# apollo510 register map
Vendor: Ambiq Micro; Series: Apollo; File version: 1.0
CPU: CM55 r1p1, little endian, MPU, FPU, double-precision FPU, DSP, I-cache, D-cache, VTOR, ITCM, DTCM, 4 interrupt priority bits, 0 interrupts, 8 SAU regions
Registers are 32-bit, read-write, reset 0x0 unless marked. A register's access mark holds for its fields unless they carry their own. Offsets are from the block's base; [hi:lo] are bit positions; {n}, {i} and the like mark numbered series; 'fields as' and 'values as' point back to an identical list.

## TIMER — Counter/Timer
Base 0x40008000
0x00 CTRL — General Timer Controls
  [31] RESET — Write to 1 to reset all timers (self-clearing)
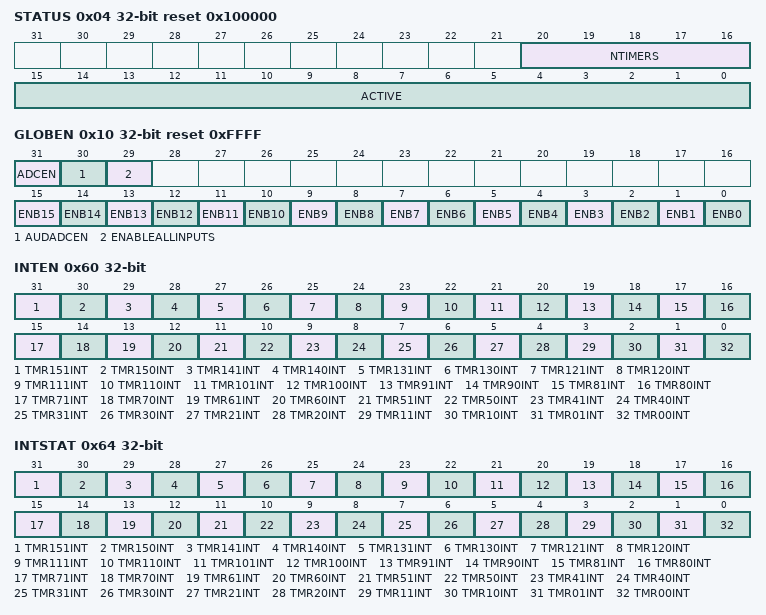
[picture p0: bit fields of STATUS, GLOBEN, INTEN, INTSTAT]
0x04 STATUS reset 0x100000 — General Timer status
  [20:16] NTIMERS — Indicates the number of timer blocks present in the design
  [15:0] ACTIVE — Indicates which timers are currnetly active (enabled)
0x10 GLOBEN reset 0xFFFF — Alternate enables for all TIMERs.
  [31] ADCEN — ADC controls enable for timer 7
    1=EN (Timer Enabled. TMREN enable is used.); 0=DIS (Disable TIMER .)
  [30] AUDADCEN — Audio ADC controls enable for timer 6
    values as ADCEN
  [29] ENABLEALLINPUTS — Override to enable all GPIO inputs
    1=EN (Override to enable all inputs from GPIO); 0=DIS (Normal mode where inputs from GPIO are enabled based on enabled clock and triggers.)
  [n] ENB{n} (n=0..15) — Alternate enable for timer {n}
    1=EN (Timer Enabled. TMR{n}EN enable is used.); 0=DIS (Disable TIMER {n}.)
0x60 INTEN — Set bits in this register to allow this module to generate the corresponding interrupt.
  [31] TMR151INT — Counter/Timer 15 interrupt based on CMP1.
  [30] TMR150INT — Counter/Timer 15 interrupt based on CMP0.
  [29] TMR141INT — Counter/Timer 14 interrupt based on CMP1.
  [28] TMR140INT — Counter/Timer 14 interrupt based on CMP0.
  [27] TMR131INT — Counter/Timer 13 interrupt based on CMP1.
  [26] TMR130INT — Counter/Timer 13 interrupt based on CMP0.
  [25] TMR121INT — Counter/Timer 12 interrupt based on CMP1.
  [24] TMR120INT — Counter/Timer 12 interrupt based on CMP0.
  [23] TMR111INT — Counter/Timer 11 interrupt based on CMP1.
  [22] TMR110INT — Counter/Timer 11 interrupt based on CMP0.
  [21] TMR101INT — Counter/Timer 10 interrupt based on CMP1.
  [20] TMR100INT — Counter/Timer 10 interrupt based on CMP0.
  [19] TMR91INT — Counter/Timer 9 interrupt based on CMP1.
  [18] TMR90INT — Counter/Timer 9 interrupt based on CMP0.
  [17] TMR81INT — Counter/Timer 8 interrupt based on CMP1.
  [16] TMR80INT — Counter/Timer 8 interrupt based on CMP0.
  [15] TMR71INT — Counter/Timer 7 interrupt based on CMP1.
  [14] TMR70INT — Counter/Timer 7 interrupt based on CMP0.
  [13] TMR61INT — Counter/Timer 6 interrupt based on CMP1.
  [12] TMR60INT — Counter/Timer 6 interrupt based on CMP0.
  [11] TMR51INT — Counter/Timer 5 interrupt based on CMP1.
  [10] TMR50INT — Counter/Timer 5 interrupt based on CMP0.
  [9] TMR41INT — Counter/Timer 4 interrupt based on CMP1.
  [8] TMR40INT — Counter/Timer 4 interrupt based on CMP0.
  [7] TMR31INT — Counter/Timer 3 interrupt based on CMP1.
  [6] TMR30INT — Counter/Timer 3 interrupt based on CMP0.
  [5] TMR21INT — Counter/Timer 2 interrupt based on CMP1.
  [4] TMR20INT — Counter/Timer 2 interrupt based on CMP0.
  [3] TMR11INT — Counter/Timer 1 interrupt based on CMP1.
  [2] TMR10INT — Counter/Timer 1 interrupt based on CMP0.
  [1] TMR01INT — Counter/Timer 0 interrupt based on CMP1.
  [0] TMR00INT — Counter/Timer 0 interrupt based on CMP0.
0x64 INTSTAT — Read bits from this register to discover the cause of a recent interrupt.
  fields as INTEN
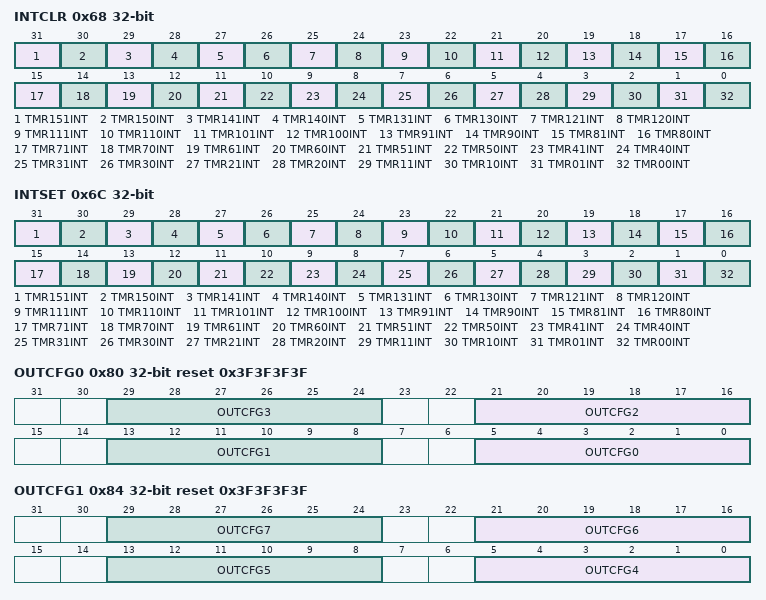
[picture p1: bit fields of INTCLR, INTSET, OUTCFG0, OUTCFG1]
0x68 INTCLR — Write a 1 to a bit in this register to clear the interrupt status associated with that bit.
  fields as INTEN
0x6C INTSET — Write a 1 to a bit in this register to instantly generate an interrupt from this module. (Generally used for testing purposes).
  fields as INTEN
0x80 OUTCFG0 reset 0x3F3F3F3F — Counter/Timer or System Timer output selections for GPIO pads.
  [all] fields
    0=TIMER00 (Output is Timer 0, output 0); 1=TIMER01 (Output is Timer 0, output 1); 2=TIMER10 (Output is Timer 1, output 0); 3=TIMER11 (Output is Timer 1, output 1); 4=TIMER20 (Output is Timer 2, output 0); 5=TIMER21 (Output is Timer 2, output 1); 6=TIMER30 (Output is Timer 3, output 0); 7=TIMER31 (Output is Timer 3, output 1); 8=TIMER40 (Output is Timer 4, output 0); 9=TIMER41 (Output is Timer 4, output 1); 10=TIMER50 (Output is Timer 5, output 0); 11=TIMER51 (Output is Timer 5, output 1); 12=TIMER60 (Output is Timer 6, output 0); 13=TIMER61 (Output is Timer 6, output 1); 14=TIMER70 (Output is Timer 7, output 0); 15=TIMER71 (Output is Timer 7, output 1); 16=TIMER80 (Output is Timer 8, output 0); 17=TIMER81 (Output is Timer 8, output 1); 18=TIMER90 (Output is Timer 9, output 0); 19=TIMER91 (Output is Timer 9, output 1); 20=TIMER100 (Output is Timer 10, output 0); 21=TIMER101 (Output is Timer 10, output 1); 22=TIMER110 (Output is Timer 11, output 0); 23=TIMER111 (Output is Timer 11, output 1); 24=TIMER120 (Output is Timer 12, output 0); 25=TIMER121 (Output is Timer 12, output 1); 26=TIMER130 (Output is Timer 13, output 0); 27=TIMER131 (Output is Timer 13, output 1); 28=TIMER140 (Output is Timer 14, output 0); 29=TIMER141 (Output is Timer 14, output 1); 30=TIMER150 (Output is Timer 15, output 0); 31=TIMER151 (Output is Timer 15, output 1); {v}=STIMER{v-32} (Output is STimer {v-32}) (v=32..39); 63=DISABLED (Output is disabled)
  [8n+5:8n] OUTCFG{n} (n=0..3) — Counter/Timer or System Timer output selection for GPIO{n}. Select an output of any timer to be output on this GPIO.
0x84 OUTCFG1 reset 0x3F3F3F3F — Counter/Timer or System Timer output selections for GPIO pads.
  [all] fields
    values as the fields of OUTCFG0
  [8n-27:8n-32] OUTCFG{n} (n=4..7) — Counter/Timer or System Timer output selection for GPIO{n}. Select an output of any timer to be output on this GPIO.
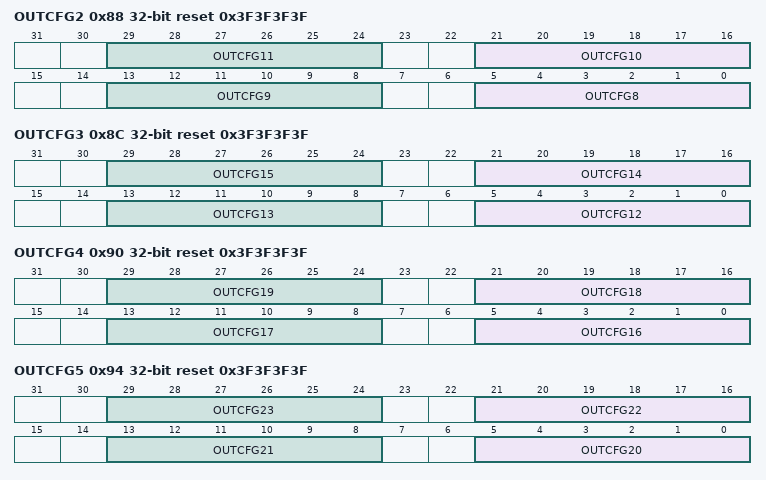
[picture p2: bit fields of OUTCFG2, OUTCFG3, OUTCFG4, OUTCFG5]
0x88 OUTCFG2 reset 0x3F3F3F3F — Counter/Timer or System Timer output selections for GPIO pads.
  [all] fields
    values as the fields of OUTCFG0
  [8n-59:8n-64] OUTCFG{n} (n=8..11) — Counter/Timer or System Timer output selection for GPIO{n}. Select an output of any timer to be output on this GPIO.
0x8C OUTCFG3 reset 0x3F3F3F3F — Counter/Timer or System Timer output selections for GPIO pads.
  [all] fields
    values as the fields of OUTCFG0
  [8n-91:8n-96] OUTCFG{n} (n=12..15) — Counter/Timer or System Timer output selection for GPIO{n}. Select an output of any timer to be output on this GPIO.
0x90 OUTCFG4 reset 0x3F3F3F3F — Counter/Timer or System Timer output selections for GPIO pads.
  [all] fields
    values as the fields of OUTCFG0
  [8n-123:8n-128] OUTCFG{n} (n=16..19) — Counter/Timer or System Timer output selection for GPIO{n}. Select an output of any timer to be output on this GPIO.
0x94 OUTCFG5 reset 0x3F3F3F3F — Counter/Timer or System Timer output selections for GPIO pads.
  [all] fields
    values as the fields of OUTCFG0
  [8n-155:8n-160] OUTCFG{n} (n=20..23) — Counter/Timer or System Timer output selection for GPIO{n}. Select an output of any timer to be output on this GPIO.
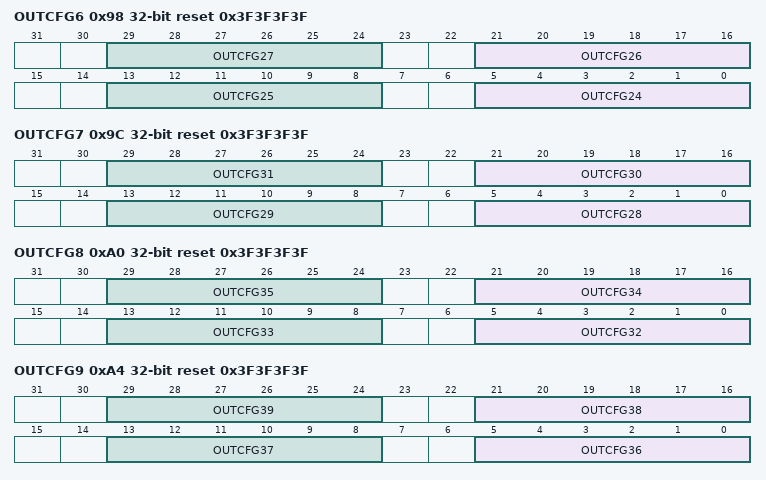
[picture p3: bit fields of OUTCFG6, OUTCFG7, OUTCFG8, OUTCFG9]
0x98 OUTCFG6 reset 0x3F3F3F3F — Counter/Timer or System Timer output selections for GPIO pads.
  [all] fields
    values as the fields of OUTCFG0
  [8n-187:8n-192] OUTCFG{n} (n=24..27) — Counter/Timer or System Timer output selection for GPIO{n}. Select an output of any timer to be output on this GPIO.
0x9C OUTCFG7 reset 0x3F3F3F3F — Counter/Timer or System Timer output selections for GPIO pads.
  [all] fields
    values as the fields of OUTCFG0
  [8n-219:8n-224] OUTCFG{n} (n=28..31) — Counter/Timer or System Timer output selection for GPIO{n}. Select an output of any timer to be output on this GPIO.
0xA0 OUTCFG8 reset 0x3F3F3F3F — Counter/Timer or System Timer output selections for GPIO pads.
  [all] fields
    values as the fields of OUTCFG0
  [8n-251:8n-256] OUTCFG{n} (n=32..35) — Counter/Timer or System Timer output selection for GPIO{n}. Select an output of any timer to be output on this GPIO.
0xA4 OUTCFG9 reset 0x3F3F3F3F — Counter/Timer or System Timer output selections for GPIO pads.
  [all] fields
    values as the fields of OUTCFG0
  [8n-283:8n-288] OUTCFG{n} (n=36..39) — Counter/Timer or System Timer output selection for GPIO{n}. Select an output of any timer to be output on this GPIO.
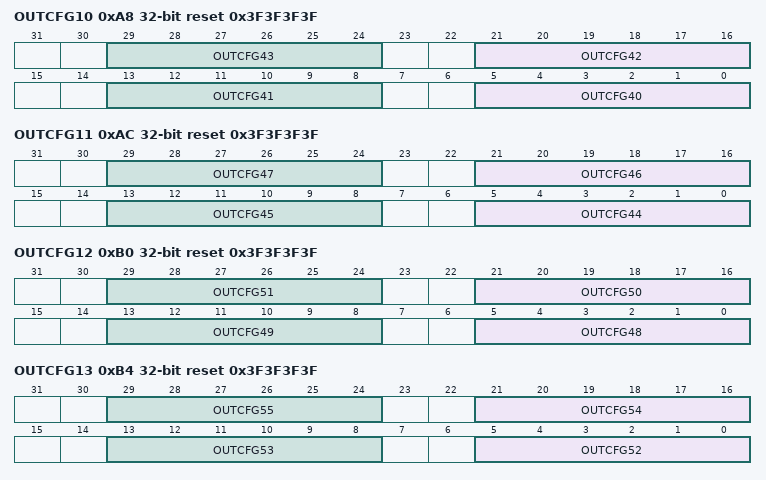
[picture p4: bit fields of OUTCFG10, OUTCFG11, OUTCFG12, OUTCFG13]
0xA8 OUTCFG10 reset 0x3F3F3F3F — Counter/Timer or System Timer output selections for GPIO pads.
  [all] fields
    values as the fields of OUTCFG0
  [8n-315:8n-320] OUTCFG{n} (n=40..43) — Counter/Timer or System Timer output selection for GPIO{n}. Select an output of any timer to be output on this GPIO.
0xAC OUTCFG11 reset 0x3F3F3F3F — Counter/Timer or System Timer output selections for GPIO pads.
  [all] fields
    values as the fields of OUTCFG0
  [8n-347:8n-352] OUTCFG{n} (n=44..47) — Counter/Timer or System Timer output selection for GPIO{n}. Select an output of any timer to be output on this GPIO.
0xB0 OUTCFG12 reset 0x3F3F3F3F — Counter/Timer or System Timer output selections for GPIO pads.
  [all] fields
    values as the fields of OUTCFG0
  [8n-379:8n-384] OUTCFG{n} (n=48..51) — Counter/Timer or System Timer output selection for GPIO{n}. Select an output of any timer to be output on this GPIO.
0xB4 OUTCFG13 reset 0x3F3F3F3F — Counter/Timer or System Timer output selections for GPIO pads.
  [all] fields
    values as the fields of OUTCFG0
  [8n-411:8n-416] OUTCFG{n} (n=52..55) — Counter/Timer or System Timer output selection for GPIO{n}. Select an output of any timer to be output on this GPIO.
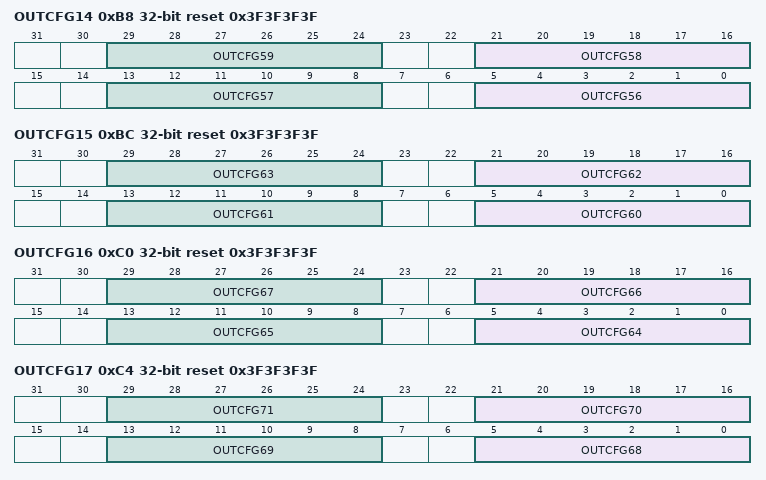
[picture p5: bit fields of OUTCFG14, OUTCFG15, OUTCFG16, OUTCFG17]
0xB8 OUTCFG14 reset 0x3F3F3F3F — Counter/Timer or System Timer output selections for GPIO pads.
  [all] fields
    values as the fields of OUTCFG0
  [8n-443:8n-448] OUTCFG{n} (n=56..59) — Counter/Timer or System Timer output selection for GPIO{n}. Select an output of any timer to be output on this GPIO.
0xBC OUTCFG15 reset 0x3F3F3F3F — Counter/Timer or System Timer output selections for GPIO pads.
  [all] fields
    values as the fields of OUTCFG0
  [8n-475:8n-480] OUTCFG{n} (n=60..63) — Counter/Timer or System Timer output selection for GPIO{n}. Select an output of any timer to be output on this GPIO.
0xC0 OUTCFG16 reset 0x3F3F3F3F — Counter/Timer or System Timer output selections for GPIO pads.
  [all] fields
    values as the fields of OUTCFG0
  [8n-507:8n-512] OUTCFG{n} (n=64..67) — Counter/Timer or System Timer output selection for GPIO{n}. Select an output of any timer to be output on this GPIO.
0xC4 OUTCFG17 reset 0x3F3F3F3F — Counter/Timer or System Timer output selections for GPIO pads.
  [all] fields
    values as the fields of OUTCFG0
  [8n-539:8n-544] OUTCFG{n} (n=68..71) — Counter/Timer or System Timer output selection for GPIO{n}. Select an output of any timer to be output on this GPIO.
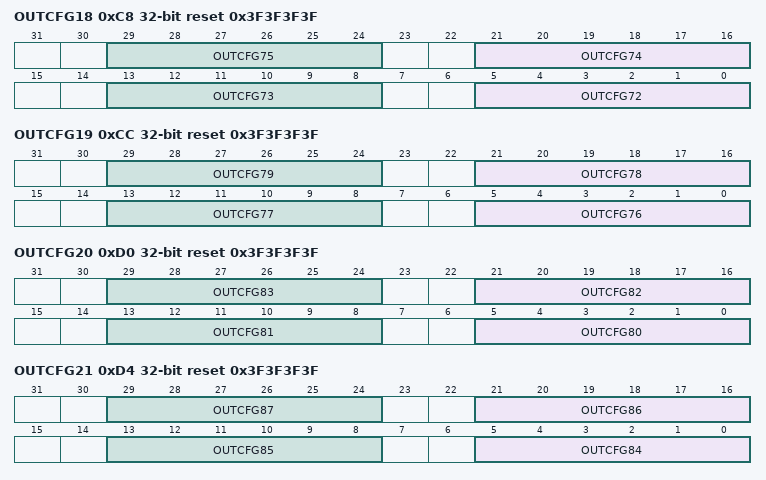
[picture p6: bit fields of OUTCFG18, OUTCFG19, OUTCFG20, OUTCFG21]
0xC8 OUTCFG18 reset 0x3F3F3F3F — Counter/Timer or System Timer output selections for GPIO pads.
  [all] fields
    values as the fields of OUTCFG0
  [8n-571:8n-576] OUTCFG{n} (n=72..75) — Counter/Timer or System Timer output selection for GPIO{n}. Select an output of any timer to be output on this GPIO.
0xCC OUTCFG19 reset 0x3F3F3F3F — Counter/Timer or System Timer output selections for GPIO pads.
  [all] fields
    values as the fields of OUTCFG0
  [8n-603:8n-608] OUTCFG{n} (n=76..79) — Counter/Timer or System Timer output selection for GPIO{n}. Select an output of any timer to be output on this GPIO.
0xD0 OUTCFG20 reset 0x3F3F3F3F — Counter/Timer or System Timer output selections for GPIO pads.
  [all] fields
    values as the fields of OUTCFG0
  [8n-635:8n-640] OUTCFG{n} (n=80..83) — Counter/Timer or System Timer output selection for GPIO{n}. Select an output of any timer to be output on this GPIO.
0xD4 OUTCFG21 reset 0x3F3F3F3F — Counter/Timer or System Timer output selections for GPIO pads.
  [all] fields
    values as the fields of OUTCFG0
  [8n-667:8n-672] OUTCFG{n} (n=84..87) — Counter/Timer or System Timer output selection for GPIO{n}. Select an output of any timer to be output on this GPIO.
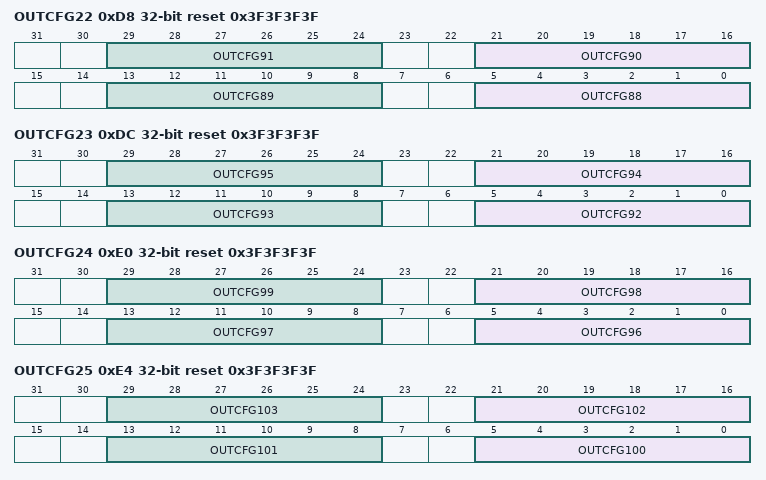
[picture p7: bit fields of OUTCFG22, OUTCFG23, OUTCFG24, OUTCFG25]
0xD8 OUTCFG22 reset 0x3F3F3F3F — Counter/Timer or System Timer output selections for GPIO pads.
  [all] fields
    values as the fields of OUTCFG0
  [8n-699:8n-704] OUTCFG{n} (n=88..91) — Counter/Timer or System Timer output selection for GPIO{n}. Select an output of any timer to be output on this GPIO.
0xDC OUTCFG23 reset 0x3F3F3F3F — Counter/Timer or System Timer output selections for GPIO pads.
  [all] fields
    values as the fields of OUTCFG0
  [8n-731:8n-736] OUTCFG{n} (n=92..95) — Counter/Timer or System Timer output selection for GPIO{n}. Select an output of any timer to be output on this GPIO.
0xE0 OUTCFG24 reset 0x3F3F3F3F — Counter/Timer or System Timer output selections for GPIO pads.
  [all] fields
    values as the fields of OUTCFG0
  [8n-763:8n-768] OUTCFG{n} (n=96..99) — Counter/Timer or System Timer output selection for GPIO{n}. Select an output of any timer to be output on this GPIO.
0xE4 OUTCFG25 reset 0x3F3F3F3F — Counter/Timer or System Timer output selections for GPIO pads.
  [all] fields
    values as the fields of OUTCFG0
  [8n-795:8n-800] OUTCFG{n} (n=100..103) — Counter/Timer or System Timer output selection for GPIO{n}. Select an output of any timer to be output on this GPIO.
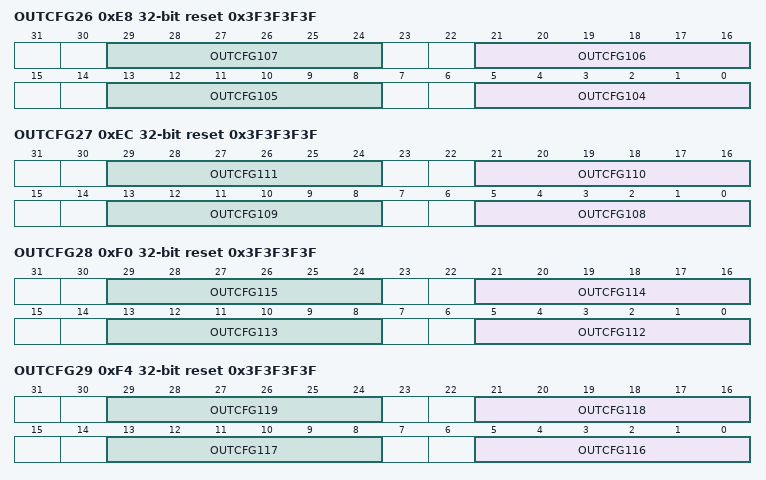
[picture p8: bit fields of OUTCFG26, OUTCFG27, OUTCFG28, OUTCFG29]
0xE8 OUTCFG26 reset 0x3F3F3F3F — Counter/Timer or System Timer output selections for GPIO pads.
  [all] fields
    values as the fields of OUTCFG0
  [8n-827:8n-832] OUTCFG{n} (n=104..107) — Counter/Timer or System Timer output selection for GPIO{n}. Select an output of any timer to be output on this GPIO.
0xEC OUTCFG27 reset 0x3F3F3F3F — Counter/Timer or System Timer output selections for GPIO pads.
  [all] fields
    values as the fields of OUTCFG0
  [8n-859:8n-864] OUTCFG{n} (n=108..111) — Counter/Timer or System Timer output selection for GPIO{n}. Select an output of any timer to be output on this GPIO.
0xF0 OUTCFG28 reset 0x3F3F3F3F — Counter/Timer or System Timer output selections for GPIO pads.
  [all] fields
    values as the fields of OUTCFG0
  [8n-891:8n-896] OUTCFG{n} (n=112..115) — Counter/Timer or System Timer output selection for GPIO{n}. Select an output of any timer to be output on this GPIO.
0xF4 OUTCFG29 reset 0x3F3F3F3F — Counter/Timer or System Timer output selections for GPIO pads.
  [all] fields
    values as the fields of OUTCFG0
  [8n-923:8n-928] OUTCFG{n} (n=116..119) — Counter/Timer or System Timer output selection for GPIO{n}. Select an output of any timer to be output on this GPIO.
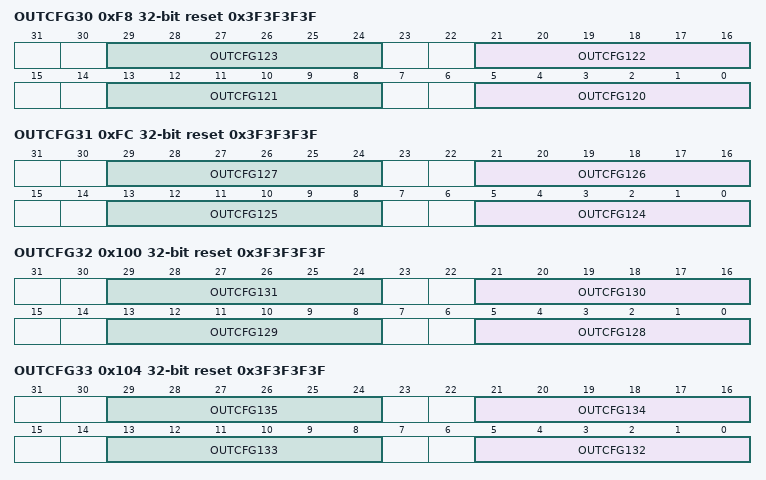
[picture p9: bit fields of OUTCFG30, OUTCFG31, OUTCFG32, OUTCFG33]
0xF8 OUTCFG30 reset 0x3F3F3F3F — Counter/Timer or System Timer output selections for GPIO pads.
  [all] fields
    values as the fields of OUTCFG0
  [8n-955:8n-960] OUTCFG{n} (n=120..123) — Counter/Timer or System Timer output selection for GPIO{n}. Select an output of any timer to be output on this GPIO.
0xFC OUTCFG31 reset 0x3F3F3F3F — Counter/Timer or System Timer output selections for GPIO pads.
  [all] fields
    values as the fields of OUTCFG0
  [8n-987:8n-992] OUTCFG{n} (n=124..127) — Counter/Timer or System Timer output selection for GPIO{n}. Select an output of any timer to be output on this GPIO.
0x100 OUTCFG32 reset 0x3F3F3F3F — Counter/Timer or System Timer output selections for GPIO pads.
  [all] fields
    values as the fields of OUTCFG0
  [8n-1019:8n-1024] OUTCFG{n} (n=128..131) — Counter/Timer or System Timer output selection for GPIO{n}. Select an output of any timer to be output on this GPIO.
0x104 OUTCFG33 reset 0x3F3F3F3F — Counter/Timer or System Timer output selections for GPIO pads.
  [all] fields
    values as the fields of OUTCFG0
  [8n-1051:8n-1056] OUTCFG{n} (n=132..135) — Counter/Timer or System Timer output selection for GPIO{n}. Select an output of any timer to be output on this GPIO.
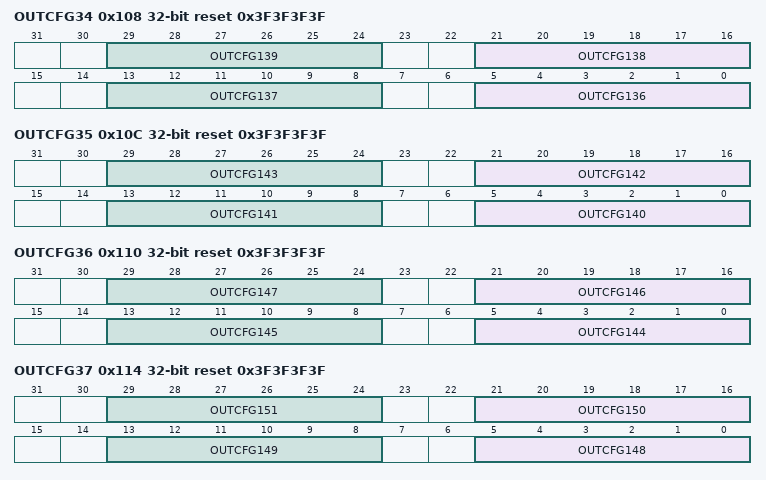
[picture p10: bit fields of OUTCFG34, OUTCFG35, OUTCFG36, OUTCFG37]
0x108 OUTCFG34 reset 0x3F3F3F3F — Counter/Timer or System Timer output selections for GPIO pads.
  [all] fields
    values as the fields of OUTCFG0
  [8n-1083:8n-1088] OUTCFG{n} (n=136..139) — Counter/Timer or System Timer output selection for GPIO{n}. Select an output of any timer to be output on this GPIO.
0x10C OUTCFG35 reset 0x3F3F3F3F — Counter/Timer or System Timer output selections for GPIO pads.
  [all] fields
    values as the fields of OUTCFG0
  [8n-1115:8n-1120] OUTCFG{n} (n=140..143) — Counter/Timer or System Timer output selection for GPIO{n}. Select an output of any timer to be output on this GPIO.
0x110 OUTCFG36 reset 0x3F3F3F3F — Counter/Timer or System Timer output selections for GPIO pads.
  [all] fields
    values as the fields of OUTCFG0
  [8n-1147:8n-1152] OUTCFG{n} (n=144..147) — Counter/Timer or System Timer output selection for GPIO{n}. Select an output of any timer to be output on this GPIO.
0x114 OUTCFG37 reset 0x3F3F3F3F — Counter/Timer or System Timer output selections for GPIO pads.
  [all] fields
    values as the fields of OUTCFG0
  [8n-1179:8n-1184] OUTCFG{n} (n=148..151) — Counter/Timer or System Timer output selection for GPIO{n}. Select an output of any timer to be output on this GPIO.
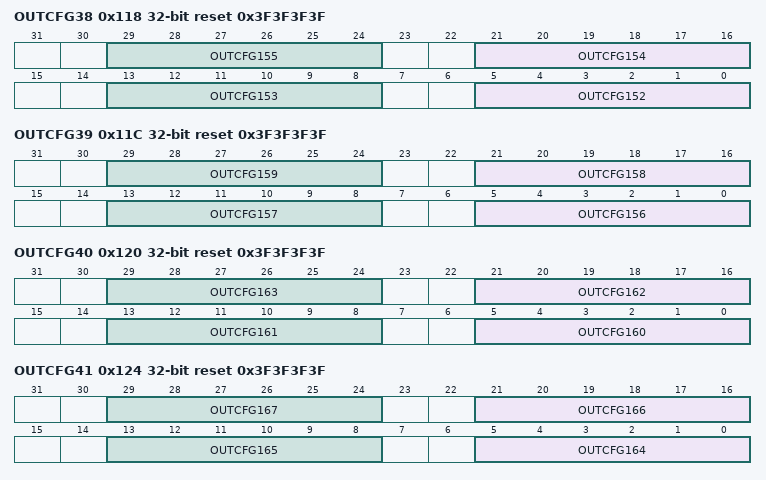
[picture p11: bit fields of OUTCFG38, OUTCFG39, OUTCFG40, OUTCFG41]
0x118 OUTCFG38 reset 0x3F3F3F3F — Counter/Timer or System Timer output selections for GPIO pads.
  [all] fields
    values as the fields of OUTCFG0
  [8n-1211:8n-1216] OUTCFG{n} (n=152..155) — Counter/Timer or System Timer output selection for GPIO{n}. Select an output of any timer to be output on this GPIO.
0x11C OUTCFG39 reset 0x3F3F3F3F — Counter/Timer or System Timer output selections for GPIO pads.
  [all] fields
    values as the fields of OUTCFG0
  [8n-1243:8n-1248] OUTCFG{n} (n=156..159) — Counter/Timer or System Timer output selection for GPIO{n}. Select an output of any timer to be output on this GPIO.
0x120 OUTCFG40 reset 0x3F3F3F3F — Counter/Timer or System Timer output selections for GPIO pads.
  [all] fields
    values as the fields of OUTCFG0
  [8n-1275:8n-1280] OUTCFG{n} (n=160..163) — Counter/Timer or System Timer output selection for GPIO{n}. Select an output of any timer to be output on this GPIO.
0x124 OUTCFG41 reset 0x3F3F3F3F — Counter/Timer or System Timer output selections for GPIO pads.
  [all] fields
    values as the fields of OUTCFG0
  [8n-1307:8n-1312] OUTCFG{n} (n=164..167) — Counter/Timer or System Timer output selection for GPIO{n}. Select an output of any timer to be output on this GPIO.
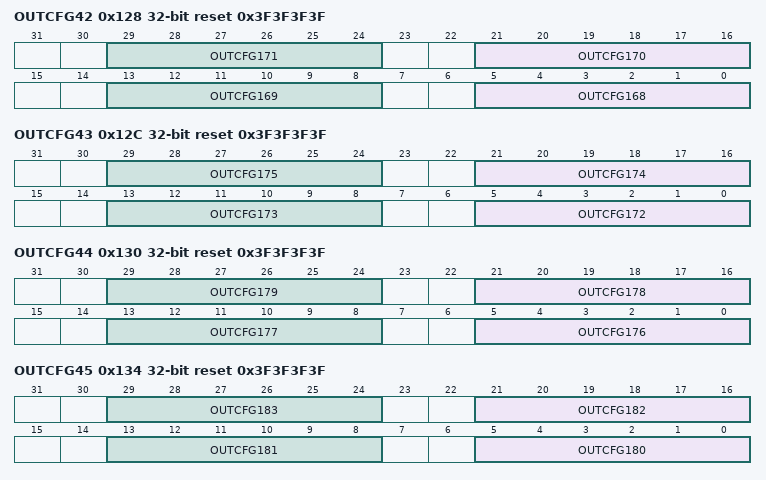
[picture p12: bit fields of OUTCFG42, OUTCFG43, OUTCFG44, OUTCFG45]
0x128 OUTCFG42 reset 0x3F3F3F3F — Counter/Timer or System Timer output selections for GPIO pads.
  [all] fields
    values as the fields of OUTCFG0
  [8n-1339:8n-1344] OUTCFG{n} (n=168..171) — Counter/Timer or System Timer output selection for GPIO{n}. Select an output of any timer to be output on this GPIO.
0x12C OUTCFG43 reset 0x3F3F3F3F — Counter/Timer or System Timer output selections for GPIO pads.
  [all] fields
    values as the fields of OUTCFG0
  [8n-1371:8n-1376] OUTCFG{n} (n=172..175) — Counter/Timer or System Timer output selection for GPIO{n}. Select an output of any timer to be output on this GPIO.
0x130 OUTCFG44 reset 0x3F3F3F3F — Counter/Timer or System Timer output selections for GPIO pads.
  [all] fields
    values as the fields of OUTCFG0
  [8n-1403:8n-1408] OUTCFG{n} (n=176..179) — Counter/Timer or System Timer output selection for GPIO{n}. Select an output of any timer to be output on this GPIO.
0x134 OUTCFG45 reset 0x3F3F3F3F — Counter/Timer or System Timer output selections for GPIO pads.
  [all] fields
    values as the fields of OUTCFG0
  [8n-1435:8n-1440] OUTCFG{n} (n=180..183) — Counter/Timer or System Timer output selection for GPIO{n}. Select an output of any timer to be output on this GPIO.
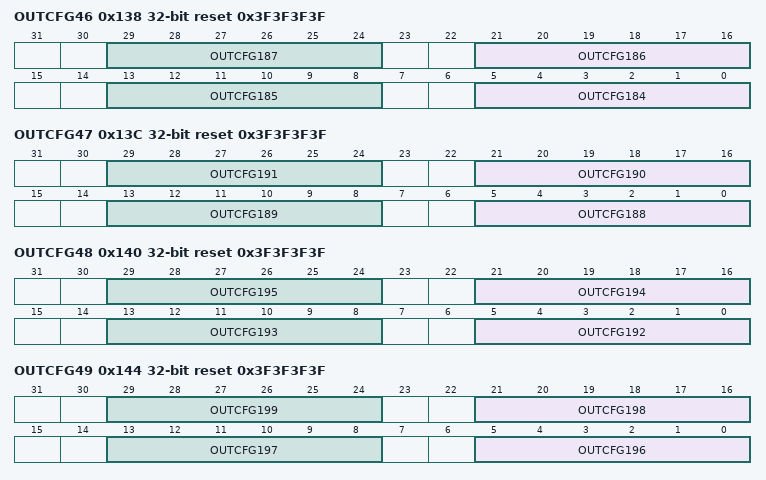
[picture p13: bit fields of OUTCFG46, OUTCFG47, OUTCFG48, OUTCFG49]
0x138 OUTCFG46 reset 0x3F3F3F3F — Counter/Timer or System Timer output selections for GPIO pads.
  [all] fields
    values as the fields of OUTCFG0
  [8n-1467:8n-1472] OUTCFG{n} (n=184..187) — Counter/Timer or System Timer output selection for GPIO{n}. Select an output of any timer to be output on this GPIO.
0x13C OUTCFG47 reset 0x3F3F3F3F — Counter/Timer or System Timer output selections for GPIO pads.
  [all] fields
    values as the fields of OUTCFG0
  [8n-1499:8n-1504] OUTCFG{n} (n=188..191) — Counter/Timer or System Timer output selection for GPIO{n}. Select an output of any timer to be output on this GPIO.
0x140 OUTCFG48 reset 0x3F3F3F3F — Counter/Timer or System Timer output selections for GPIO pads.
  [all] fields
    values as the fields of OUTCFG0
  [8n-1531:8n-1536] OUTCFG{n} (n=192..195) — Counter/Timer or System Timer output selection for GPIO{n}. Select an output of any timer to be output on this GPIO.
0x144 OUTCFG49 reset 0x3F3F3F3F — Counter/Timer or System Timer output selections for GPIO pads.
  [all] fields
    values as the fields of OUTCFG0
  [8n-1563:8n-1568] OUTCFG{n} (n=196..199) — Counter/Timer or System Timer output selection for GPIO{n}. Select an output of any timer to be output on this GPIO.
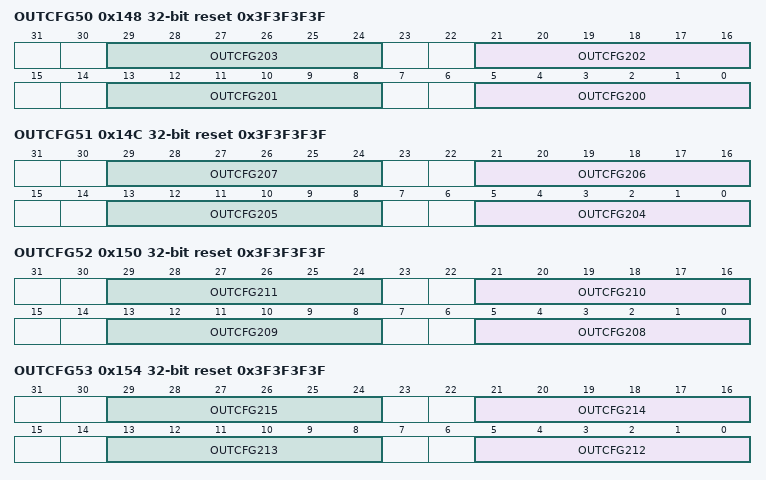
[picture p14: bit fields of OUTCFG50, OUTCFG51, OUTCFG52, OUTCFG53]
0x148 OUTCFG50 reset 0x3F3F3F3F — Counter/Timer or System Timer output selections for GPIO pads.
  [all] fields
    values as the fields of OUTCFG0
  [8n-1595:8n-1600] OUTCFG{n} (n=200..203) — Counter/Timer or System Timer output selection for GPIO{n}. Select an output of any timer to be output on this GPIO.
0x14C OUTCFG51 reset 0x3F3F3F3F — Counter/Timer or System Timer output selections for GPIO pads.
  [all] fields
    values as the fields of OUTCFG0
  [8n-1627:8n-1632] OUTCFG{n} (n=204..207) — Counter/Timer or System Timer output selection for GPIO{n}. Select an output of any timer to be output on this GPIO.
0x150 OUTCFG52 reset 0x3F3F3F3F — Counter/Timer or System Timer output selections for GPIO pads.
  [all] fields
    values as the fields of OUTCFG0
  [8n-1659:8n-1664] OUTCFG{n} (n=208..211) — Counter/Timer or System Timer output selection for GPIO{n}. Select an output of any timer to be output on this GPIO.
0x154 OUTCFG53 reset 0x3F3F3F3F — Counter/Timer or System Timer output selections for GPIO pads.
  [all] fields
    values as the fields of OUTCFG0
  [8n-1691:8n-1696] OUTCFG{n} (n=212..215) — Counter/Timer or System Timer output selection for GPIO{n}. Select an output of any timer to be output on this GPIO.
0x158 OUTCFG54 reset 0x3F3F3F3F — Counter/Timer or System Timer output selections for GPIO pads.
  [all] fields
    values as the fields of OUTCFG0
  [8n-1723:8n-1728] OUTCFG{n} (n=216..219) — Counter/Timer or System Timer output selection for GPIO{n}. Select an output of any timer to be output on this GPIO.
0x15C OUTCFG55 reset 0x3F3F3F3F — Counter/Timer or System Timer output selections for GPIO pads.
  [all] fields
    values as the fields of OUTCFG0
  [8n-1755:8n-1760] OUTCFG{n} (n=220..223) — Counter/Timer or System Timer output selection for GPIO{n}. Select an output of any timer to be output on this GPIO.
{0x200+0x20*i} CTRL{i} (i=0..15) — This includes the Control bit fields for timer {i}.
  [31:24] TMR{i}LMT — This field decides the number of iterations of Counter/Timer {i}. For Single/Repeat Patterns, it indicates number of bits to be shifted out and so, max value is 63.
  [18:17] TMR{i}TMODE — Counter/Timer {i} Trigger Mode
    0=DIS (Trigger not enabled); 1=RISE (Trigger on rising edge of TRIGSEL source); 2=FALL (Trigger on falling edge of TRIGSEL source); 3=BOTH (Trigger on either edge of TRIGSEL source)
  [16:8] TMR{i}CLK — Counter/Timer {i} Clock Select. Note: Any GPIO can be used as a clock source.
    0=HFRC_DIV4 (Clock source is the HFRC / 4); 1=HFRC_DIV16 (Clock source is HFRC / 16); 2=HFRC_DIV64 (Clock source is HFRC / 64); 3=HFRC_DIV256 (Clock source is HFRC / 256); 4=HFRC_DIV1024 (Clock source is HFRC / 1024); 5=HFRC_DIV4K (Clock source is HFRC / 4096); 6=LFRC (Clock source is LFRC); 7=LFRC_DIV2 (Clock source is LFRC / 2); 8=LFRC_DIV32 (Clock source is LFRC / 32); 9=LFRC_DIV1K (Clock source is LFRC / 1024); 10=XT (Clock source is the XT (uncalibrated).); 11=XT_DIV2 (Clock source is XT / 2); 12=XT_DIV4 (Clock source is XT / 4); 13=XT_DIV8 (Clock source is XT / 8); 14=XT_DIV16 (Clock source is XT / 16); 15=XT_DIV32 (Clock source is XT / 32); 16=XT_DIV128 (Clock source is XT / 128); 17=RTC_100HZ (Clock source is 100 Hz from the current RTC oscillator.); 18=XT_512Hz (Clock source is XT / 64); 19=HFRC2_125MHz_DIV8 (HFRC2_16MHz); 20=HFRC2_125MHz_DIV16 (HFRC2_8MHz); 21=HFRC2_125MHz_DIV32 (HFRC2_4MHz); 22=HFRC2_125MHz_DIV64 (HFRC2_2MHz); 23=HFRC2_125MHz_DIV128 (HFRC2_1MHz); 24=HFRC2_125MHz_DIV256 (HFRC2_512KHz); 25=XTAL_HS (HF XTAL 32MHz); 26=XTAL_HS_DIV2 (HF XTAL 16MHz); 27=XTAL_HS_DIV4 (HF XTAL 8MHz); 28=BUCKC (Clock source is Buck VDDC TON pulses.); 29=BUCKF (Clock source is Buck VDDF TON pulses.); 30=BUCKS (Clock source is Buck VDDS TON pulses.); 31=BUCKC_LV (Clock source is Buck VDDC_LV TON pulses.); 32=TMR00 (Clock source is TIMER 0 Output 0); 33=TMR01 (Clock source is TIMER 0 Output 1); 34=TMR10 (Clock source is TIMER 1 Output 0); 35=TMR11 (Clock source is TIMER 1 Output 1); 36=TMR20 (Clock source is TIMER 2 Output 0); 37=TMR21 (Clock source is TIMER 2 Output 1); 38=TMR30 (Clock source is TIMER 3 Output 0); 39=TMR31 (Clock source is TIMER 3 Output 1); 40=TMR40 (Clock source is TIMER 4 Output 0); 41=TMR41 (Clock source is TIMER 4 Output 1); 42=TMR50 (Clock source is TIMER 5 Output 0); 43=TMR51 (Clock source is TIMER 5 Output 1); 44=TMR60 (Clock source is TIMER 6 Output 0); 45=TMR61 (Clock source is TIMER 6 Output 1); 46=TMR70 (Clock source is TIMER 7 Output 0); 47=TMR71 (Clock source is TIMER 7 Output 1); 48=TMR80 (Clock source is TIMER 8 Output 0); 49=TMR81 (Clock source is TIMER 8 Output 1); 50=TMR90 (Clock source is TIMER 9 Output 0); 51=TMR91 (Clock source is TIMER 9 Output 1); 52=TMR100 (Clock source is TIMER 10 Output 0); 53=TMR101 (Clock source is TIMER 10 Output 1); 54=TMR110 (Clock source is TIMER 11 Output 0); 55=TMR111 (Clock source is TIMER 11 Output 1); 56=TMR120 (Clock source is TIMER 12 Output 0); 57=TMR121 (Clock source is TIMER 12 Output 1); 58=TMR130 (Clock source is TIMER 13 Output 0); 59=TMR131 (Clock source is TIMER 13 Output 1); 60=TMR140 (Clock source is TIMER 14 Output 0); 61=TMR141 (Clock source is TIMER 14 Output 1); 62=TMR150 (Clock source is TIMER 15 Output 0); 63=TMR151 (Clock source is TIMER 15 Output 1); 0x100=GPIO0 (GPIO #0 is clock source.); 0x101=GPIO #n is clock source where n ranges from 0-223. The values for GPIO0 - GPIO223 are in the range 0x100 - 0x1DF, i.e. GPIO0 + n.; 0x1DF=GPIO223 (GPIO #223 is clock source.)
  [7:4] TMR{i}FN — Counter/Timer {i} Function Select. For all Functions, CMP0 marks the end of timer cycle, and thus restarts the timer.
    1=EDGE (This Mode generates a single edge on OUT0/OUT1 when TIMER value hits CMP0/CMP1 respectively. OUT[0]=0, counter increments to CMP0, OUT[0]=1, counter stops. OUT[1] follows CMP1.); 2=UPCOUNT (This mode is run up counter generating a pulse on CMP. OUT[0]/OUT[1] is pulsed for one source clock period when TIMER matches CMP0/CMP1 respectively. Timer repeats for TMR_LMT iterations.); 4=PWM (PWM mode. OUT0 and OUT1 are waveforms, and not just one clock pulse. CMP1 dictates the low phase of the output and CMP0 dictates the period. OUT[1]=~OUT[0].); 12=SINGLEPATTERN (Single pattern. OUT0=CMP0[TIMER], OUT1=CMP1[TIMER]. LMT field specifies length of pattern. When LMT GT 32 OUT0 and OUT1 is the same 64-bit pattern consisting of concatenated CMP1,CMP0. When LMT LT 32 OUT0 and OUT1 are independent. Both OUT0 and OUT1 can be inverted individually applications with POL0/POL1 = 0x1.); 13=REPEATPATTERN (Repeated pattern. Like SINGLEPATTERN mode, but pattern repeats after reaching LMT.)
  [3] TMR{i}POL1 — Counter/Timer {i} output 1 polarity.
    0=NORMAL (The polarity of the TMR{i}OUT1 pin is the same as the timer output.); 1=INVERTED (The polarity of the TMR{i}OUT1 pin is the inverse of the timer output.)
  [2] TMR{i}POL0 — Counter/Timer {i} output 0 polarity.
    0=NORMAL (The polarity of the TMR{i}OUT0 pin is the same as the timer output.); 1=INVERTED (The polarity of the TMR{i}OUT0 pin is the inverse of the timer output.)
  [1] TMR{i}CLR — Counter/Timer Clear bit.
    1=CLEAR (When written to a 1, the timer will automatically be cleared to its reset state # (0 for count up counter, CMP0 for down counter)); 0=DEFAULT (Default value set to 0. Timer works normally.)
  [0] TMR{i}EN — Counter/Timer {i} Enable bit.
    0=DIS (Counter/Timer {i} Disable.); 1=EN (Counter/Timer {i} Enable.)
{0x204+0x20*i} TIMER{i} (i=0..15) — This register holds the running time or event count for timer {i}.
  [31:0] TIMER{i} — Counter/Timer {i}
{0x208+0x20*i} TMR{i}CMP0 (i=0..15) — This contains the Compare limits for timer {i}. This is the primary comparator that can be used to mark the END of a timer cycle (and thus restart the timer for repeat modes)
  [31:0] TMR{i}CMP0 — Counter/Timer {i} End Compare Register. For MEASURE mode indicates the high phase sample count.
{0x20C+0x20*i} TMR{i}CMP1 (i=0..15) — This comparator is used as a secondary compare count for modes that generate pulses. For MEASURE mode indicates the low phase sample count.
  [31:0] TMR{i}CMP1 — Holds the secondary comparator that can be used to generate a PWM or generate secondary pulses. CMP0 should ALWAYS be used first.
{0x210+0x20*i} MODE{i} (i=0..15) — The mode register contains optional mode controls for the timer
  [16:8] TMR{i}TRIGSEL — Counter/Timer {i} Trigger Source Selection
    0=TMR00 (Trigger source is TIMER 0 Output 0); 1=TMR01 (Trigger source is TIMER 0 Output 1); 2=TMR10 (Trigger source is TIMER 1 Output 0); 3=TMR11 (Trigger source is TIMER 1 Output 1); 4=TMR20 (Trigger source is TIMER 2 Output 0); 5=TMR21 (Trigger source is TIMER 2 Output 1); 6=TMR30 (Trigger source is TIMER 3 Output 0); 7=TMR31 (Trigger source is TIMER 3 Output 1); 8=TMR40 (Trigger source is TIMER 4 Output 0); 9=TMR41 (Trigger source is TIMER 4 Output 1); 10=TMR50 (Trigger source is TIMER 5 Output 0); 11=TMR51 (Trigger source is TIMER 5 Output 1); 12=TMR60 (Trigger source is TIMER 6 Output 0); 13=TMR61 (Trigger source is TIMER 6 Output 1); 14=TMR70 (Trigger source is TIMER 7 Output 0); 15=TMR71 (Trigger source is TIMER 7 Output 1); 16=TMR80 (Trigger source is TIMER 8 Output 0); 17=TMR81 (Trigger source is TIMER 8 Output 1); 18=TMR90 (Trigger source is TIMER 9 Output 0); 19=TMR91 (Trigger source is TIMER 9 Output 1); 20=TMR100 (Trigger source is TIMER 10 Output 0); 21=TMR101 (Trigger source is TIMER 10 Output 1); 22=TMR110 (Trigger source is TIMER 11 Output 0); 23=TMR111 (Trigger source is TIMER 11 Output 1); 24=TMR120 (Trigger source is TIMER 12 Output 0); 25=TMR121 (Trigger source is TIMER 12 Output 1); 26=TMR130 (Trigger source is TIMER 13 Output 0); 27=TMR131 (Trigger source is TIMER 13 Output 1); 28=TMR140 (Trigger source is TIMER 14 Output 0); 29=TMR141 (Trigger source is TIMER 14 Output 1); 30=TMR150 (Trigger source is TIMER 15 Output 0); 31=TMR151 (Trigger source is TIMER 15 Output 1); 48=STMRCMP00 (Trigger source is STIMER Compare 0); 49=STMRCMP10 (Trigger source is STIMER Compare 1); 50=STMRCMP20 (Trigger source is STIMER Compare 2); 51=STMRCMP30 (Trigger source is STIMER Compare 3); 52=STMRCMP40 (Trigger source is STIMER Compare 4); 53=STMRCMP50 (Trigger source is STIMER Compare 5); 54=STMRCMP60 (Trigger source is STIMER Compare 6); 55=STMRCMP70 (Trigger source is STIMER Compare 7); 56=STMRCAP00 (Trigger source is STIMER Capture 0); 57=STMRCAP10 (Trigger source is STIMER Capture 1); 58=STMRCAP20 (Trigger source is STIMER Capture 2); 59=STMRCAP30 (Trigger source is STIMER Capture 3); 0x100=GPIO0 (Trigger source is GPIO #0); 0x101=GPIO #n is trigger source where n ranges from 0-223. The values for GPIO0 - GPIO223 are in the range 0x100 - 0x1DF, i.e. GPIO0 + n.; 0x1DF=GPIO223 (Trigger source is GPIO #223 (b))
{0x214+0x20*i} TMR{i}LMTVAL (i=0..15) — This is an internal counter in the hardware that counts down from TMR_LMT to 1
  [7:0] TMR{i}LMTVAL — Counter/Timer {i} Limit Readback
0x3F8 TIMERSPARES — Timer Spare Regs
  [31:0] TMRSPARES — Placeholer spare registes that can be used as needed for future use
